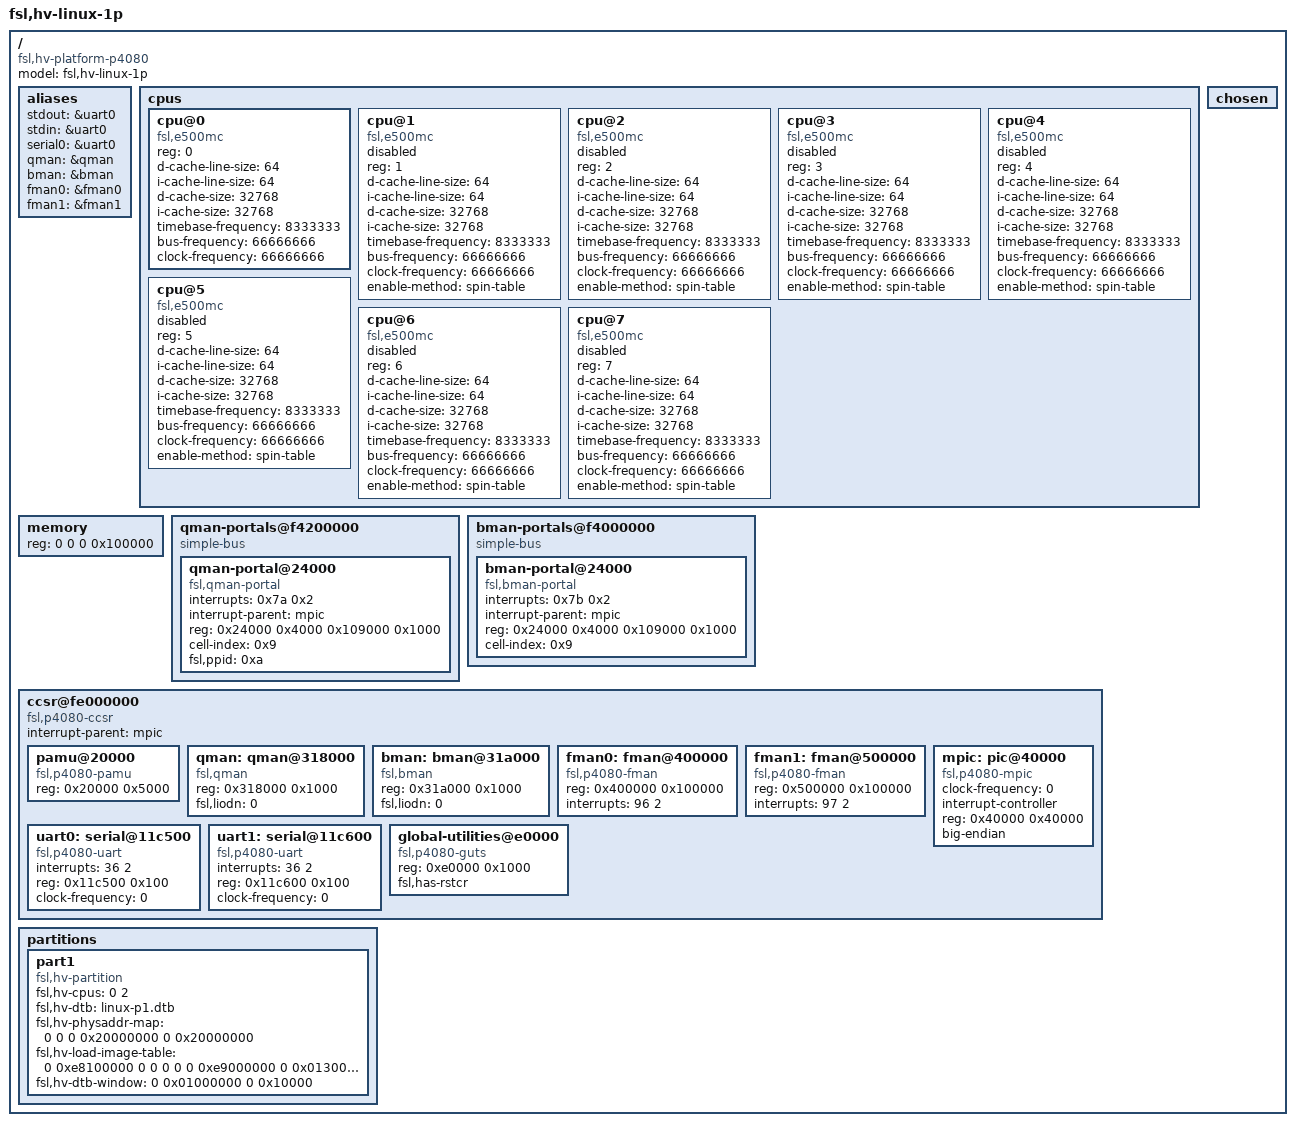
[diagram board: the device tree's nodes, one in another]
/dts-v1/;

/ {
	compatible = "fsl,hv-platform-p4080";
	model = "fsl,hv-linux-1p";
	#address-cells = <2>;
	#size-cells = <2>;

	aliases {
		stdout = &uart0;
		stdin = &uart0;
		serial0 = &uart0;
		qman = &qman;
		bman = &bman;
		fman0 = &fman0;
		fman1 = &fman1;
	};

	cpus {
		#address-cells = <1>;
		#size-cells = <0>;

		cpu@0 {
			device_type = "cpu";
			compatible = "fsl,e500mc";
			reg = <0>;
			d-cache-line-size = <64>;
			i-cache-line-size = <64>;
			d-cache-size = <32768>;
			i-cache-size = <32768>;
			timebase-frequency = <8333333>;
			bus-frequency = <66666666>;
			clock-frequency = <66666666>;
			status = "okay";
		};
		cpu@1 {
			device_type = "cpu";
			compatible = "fsl,e500mc";
			reg = <1>;
			d-cache-line-size = <64>;
			i-cache-line-size = <64>;
			d-cache-size = <32768>;
			i-cache-size = <32768>;
			timebase-frequency = <8333333>;
			bus-frequency = <66666666>;
			clock-frequency = <66666666>;
			status = "disabled";
			enable-method = "spin-table";
		};

		cpu@2 {
			device_type = "cpu";
			compatible = "fsl,e500mc";
			reg = <2>;
			d-cache-line-size = <64>;
			i-cache-line-size = <64>;
			d-cache-size = <32768>;
			i-cache-size = <32768>;
			timebase-frequency = <8333333>;
			bus-frequency = <66666666>;
			clock-frequency = <66666666>;
			status = "disabled";
			enable-method = "spin-table";
		};

		cpu@3 {
			device_type = "cpu";
			compatible = "fsl,e500mc";
			reg = <3>;
			d-cache-line-size = <64>;
			i-cache-line-size = <64>;
			d-cache-size = <32768>;
			i-cache-size = <32768>;
			timebase-frequency = <8333333>;
			bus-frequency = <66666666>;
			clock-frequency = <66666666>;
			status = "disabled";
			enable-method = "spin-table";
		};

		cpu@4 {
			device_type = "cpu";
			compatible = "fsl,e500mc";
			reg = <4>;
			d-cache-line-size = <64>;
			i-cache-line-size = <64>;
			d-cache-size = <32768>;
			i-cache-size = <32768>;
			timebase-frequency = <8333333>;
			bus-frequency = <66666666>;
			clock-frequency = <66666666>;
			status = "disabled";
			enable-method = "spin-table";
		};

		cpu@5 {
			device_type = "cpu";
			compatible = "fsl,e500mc";
			reg = <5>;
			d-cache-line-size = <64>;
			i-cache-line-size = <64>;
			d-cache-size = <32768>;
			i-cache-size = <32768>;
			timebase-frequency = <8333333>;
			bus-frequency = <66666666>;
			clock-frequency = <66666666>;
			status = "disabled";
			enable-method = "spin-table";
		};

		cpu@6 {
			device_type = "cpu";
			compatible = "fsl,e500mc";
			reg = <6>;
			d-cache-line-size = <64>;
			i-cache-line-size = <64>;
			d-cache-size = <32768>;
			i-cache-size = <32768>;
			timebase-frequency = <8333333>;
			bus-frequency = <66666666>;
			clock-frequency = <66666666>;
			status = "disabled";
			enable-method = "spin-table";
		};

		cpu@7 {
			device_type = "cpu";
			compatible = "fsl,e500mc";
			reg = <7>;
			d-cache-line-size = <64>;
			i-cache-line-size = <64>;
			d-cache-size = <32768>;
			i-cache-size = <32768>;
			timebase-frequency = <8333333>;
			bus-frequency = <66666666>;
			clock-frequency = <66666666>;
			status = "disabled";
			enable-method = "spin-table";
		};
	};

	memory {
		reg = <0 0 0 0x100000>;
		device_type = "memory";
	};

	qman-portals@f4200000 {
		#address-cells = <0x1>;
		#size-cells = <0x1>;
		compatible = "simple-bus";
		ranges = <0 0 0xf4200000 0x200000>;
		qman-portal@24000 {
			interrupts = <0x7a 0x2>;
			interrupt-parent = <&mpic>;
			compatible = "fsl,qman-portal";
			reg = <0x24000 0x4000 0x109000 0x1000>;
			cell-index = <0x9>;
			fsl,ppid = <0xa>;
		};
	};

	bman-portals@f4000000 {
		#address-cells = <0x1>;
		#size-cells = <0x1>;
		compatible = "simple-bus";
		ranges = <0 0 0xf4000000 0x200000>;
		bman-portal@24000 {
			interrupts = <0x7b 0x2>;
			interrupt-parent = <&mpic>;
			compatible = "fsl,bman-portal";
			reg = <0x24000 0x4000 0x109000 0x1000>;
			cell-index = <0x9>;
		};
	};

	ccsr@fe000000 {
		#address-cells = <1>;
		#size-cells = <1>;
		compatible = "fsl,p4080-ccsr", "simple-bus";
		ranges = <0 0 0xfe000000 0x400000>;
		interrupt-parent = <&mpic>;

		pamu@20000 {
			compatible = "fsl,p4080-pamu";
			reg = <0x20000 0x5000>;
		};

		qman: qman@318000 {
			compatible = "fsl,qman";
			reg = <0x318000 0x1000>;
			fsl,liodn = <0>;  // set by u-boot
		};

		bman: bman@31a000 {
			compatible = "fsl,bman";
			reg = <0x31a000 0x1000>;
			fsl,liodn = <0>;  // set by u-boot
		};

		fman0: fman@400000 {
			compatible = "fsl,p4080-fman", "fsl,fman";
			reg = <0x400000 0x100000>;
			interrupts = <96 2>;
		};

		fman1: fman@500000 {
			compatible = "fsl,p4080-fman", "fsl,fman";
			reg = <0x500000 0x100000>;
			interrupts = <97 2>;
		};

		mpic: pic@40000 {
			clock-frequency = <0>;
			interrupt-controller;
			#address-cells = <0>;
			#interrupt-cells = <2>;
			reg = <0x40000 0x40000>;
			compatible = "fsl,p4080-mpic", "fsl,mpic",
			             "chrp,open-pic";
			device_type = "open-pic";
			big-endian;
		};

		uart0: serial@11c500 {
			device_type = "serial";
			compatible = "fsl,p4080-uart", "fsl,ns16550", "ns16550";
			interrupts = <36 2>;
			reg = <0x11c500 0x100>;
			clock-frequency = <0>;
		};

		uart1: serial@11c600 {
			device_type = "serial";
			compatible = "fsl,p4080-uart", "fsl,ns16550", "ns16550";
			interrupts = <36 2>;
			reg = <0x11c600 0x100>;
			clock-frequency = <0>;
		};

		global-utilities@e0000 {	//global utilities block
			compatible = "fsl,p4080-guts";
			reg = <0xe0000 0x1000>;
			fsl,has-rstcr;
		};
	};

	partitions {
		part1 {
			compatible = "fsl,hv-partition";
			fsl,hv-cpus = <0 2>;
			fsl,hv-dtb = /incbin/("linux-p1.dtb");
			fsl,hv-physaddr-map = <0 0 0 0x20000000 0 0x20000000>;
			fsl,hv-load-image-table = <0 0xe8100000 0 0 0 0
			                           0 0xe9000000 0 0x01300000 0 0x00800000>;
			fsl,hv-dtb-window = <0 0x01000000 0 0x10000>;
		};
	};

	chosen {
	};
};
